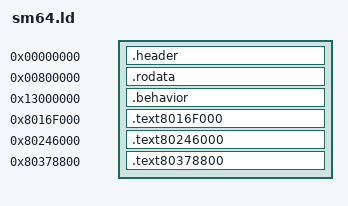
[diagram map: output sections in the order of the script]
/* Super Mario 64 linker script
 * generated by n64split v0.4a - N64 ROM splitter */

OUTPUT_FORMAT ("elf32-bigmips", "elf32-bigmips", "elf32-littlemips")
OUTPUT_ARCH (mips)

SECTIONS
{
   /* header and boot */
   .header 0x0 : AT(0x0) {
      * (.header);
      * (.boot);
   }

   /* load MIO0 and level data at 0x800000 */
   .rodata 0x800000 : {
      FILL (0x01) /* fill unused with 0x01 */
      * (.mio0);
      * (.rodata);
      * (.data);
      * (.MIPS.abiflags);
      . = ALIGN(0x10);
   }

   /* use segmented addressing for behaviors */
   .behavior 0x13000000 : AT( LOADADDR(.rodata) + SIZEOF(.rodata) ) {
      FILL (0x01) /* fill unused with 0x01 */
      * (.behavior);
      behavior_length = . - 0x13000000;
      /* default 4MB data (12MB ROM) */
      . = 0x400000 - SIZEOF(.rodata);
   }
   __load_behavior_data = LOADADDR(.behavior);
   __load_behavior_data_end = LOADADDR(.behavior) + behavior_length;

   /* (0x8016F000, 0x801B99DF, 0x7FF4FB40), // 21F4C0-269EA0 [4A9E0] */
   .text8016F000 0x8016F000 : AT(0x21F4C0) {
      * (.text8016F000);
   }

   /* (0x80246000, 0x8033A57F, 0x80245000), // 001000-0F5580 [F4580] */
   .text80246000 0x80246000 : AT(0x001000) {
      * (.text80246000);
   }

   /* (0x80378800, 0x8038BC8F, 0x80283280), // 0F5580-108A10 [13490] */
   .text80378800 0x80378800 : AT(0x0F5580) {
      * (.text80378800);
   }

}
